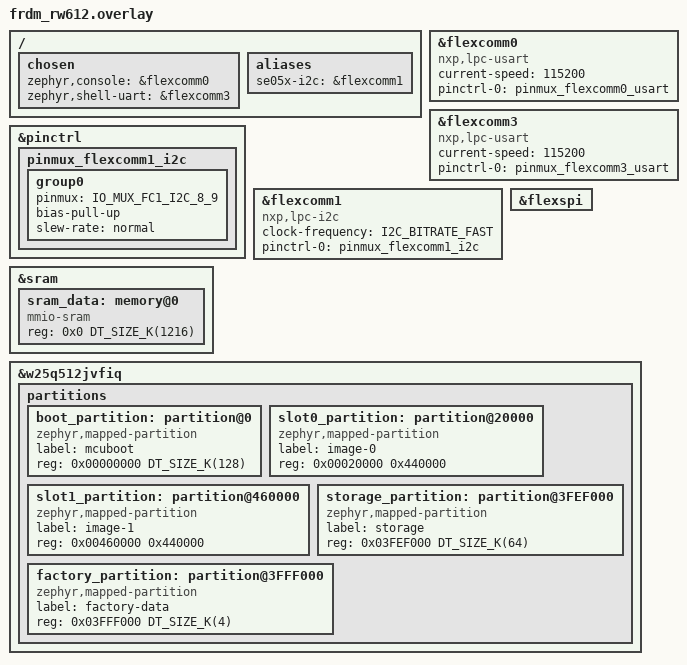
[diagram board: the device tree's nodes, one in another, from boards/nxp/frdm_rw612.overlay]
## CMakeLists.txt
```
#
#    Copyright (c) 2026 Project CHIP Authors
#
#    Licensed under the Apache License, Version 2.0 (the "License");
#    you may not use this file except in compliance with the License.
#    You may obtain a copy of the License at
#
#        http://www.apache.org/licenses/LICENSE-2.0
#
#    Unless required by applicable law or agreed to in writing, software
#    distributed under the License is distributed on an "AS IS" BASIS,
#    WITHOUT WARRANTIES OR CONDITIONS OF ANY KIND, either express or implied.
#    See the License for the specific language governing permissions and
#    limitations under the License.
#
cmake_minimum_required(VERSION 3.20)

# You may point this at a header that defines chip::app::AllDevices::AppTask as the
# final type of a CRTP layer chain rooted at AppTaskBase (see include/AppTask.h).
if(NOT DEFINED APP_TASK_IMPL_HEADER)
    set(APP_TASK_IMPL_HEADER "")
endif()

# Zephyr auto-discovers files directly under boards/. This also discovers
# board files in the registered vendor subdirectories.
include(${CMAKE_CURRENT_SOURCE_DIR}/cmake/board_files.cmake)
if(DEFINED BOARD)
    all_devices_board_name(${BOARD} ALL_DEVICES_BOARD_NAME)

    if(NOT SYSBUILD)
        all_devices_find_board_file(${CMAKE_CURRENT_SOURCE_DIR}/boards ${ALL_DEVICES_BOARD_NAME}.overlay
                                     ALL_DEVICES_NESTED_BOARD_OVERLAY EXCLUDE_FLAT)
        if(ALL_DEVICES_NESTED_BOARD_OVERLAY)
            list(APPEND DTC_OVERLAY_FILE ${ALL_DEVICES_NESTED_BOARD_OVERLAY})
            set(DTC_OVERLAY_FILE "${DTC_OVERLAY_FILE}" CACHE STRING "Application devicetree overlays" FORCE)
        endif()
    else()
        all_devices_find_board_file(${CMAKE_CURRENT_SOURCE_DIR}/boards ${ALL_DEVICES_BOARD_NAME}.overlay
                                     ALL_DEVICES_NESTED_BOARD_OVERLAY EXCLUDE_FLAT)
        list(REMOVE_ITEM DTC_OVERLAY_FILE ${ALL_DEVICES_NESTED_BOARD_OVERLAY})
        set(DTC_OVERLAY_FILE "${DTC_OVERLAY_FILE}" CACHE STRING "Application devicetree overlays" FORCE)
    endif()
    message(VERBOSE "BOARD=${BOARD} ALL_DEVICES_BOARD_NAME=${ALL_DEVICES_BOARD_NAME} ALL_DEVICES_NESTED_BOARD_OVERLAY=${ALL_DEVICES_NESTED_BOARD_OVERLAY} EXTRA_DTC_OVERLAY_FILE=${EXTRA_DTC_OVERLAY_FILE}")

    all_devices_find_board_file(${CMAKE_CURRENT_SOURCE_DIR}/boards ${ALL_DEVICES_BOARD_NAME}.conf
                                 ALL_DEVICES_NESTED_BOARD_CONF EXCLUDE_FLAT)
    if(ALL_DEVICES_NESTED_BOARD_CONF)
        list(APPEND EXTRA_CONF_FILE ${ALL_DEVICES_NESTED_BOARD_CONF})
    endif()

endif()

find_package(Zephyr HINTS $ENV{ZEPHYR_BASE})

# Matter is the Zephyr module "connectedhomeip"; it must be in the west manifest.
if(NOT DEFINED ZEPHYR_CONNECTEDHOMEIP_MODULE_DIR)
    message(FATAL_ERROR "Matter is not registered as a Zephyr module. Add it to your west manifest.")
endif()
set(CHIP_ROOT ${ZEPHYR_CONNECTEDHOMEIP_MODULE_DIR})
set(ALL_DEVICES_COMMON_DIR ${CHIP_ROOT}/examples/all-devices-app/all-devices-common)

# Device selection comes from Kconfig (CONFIG_ALL_DEVICES_DEVICE_*, see Kconfig.devices).
# -DALL_DEVICES_ENABLED_DEVICES="on-off-light;..." overrides it; an empty list means all devices.
if(NOT DEFINED ALL_DEVICES_ENABLED_DEVICES)
    set(ALL_DEVICES_ENABLED_DEVICES "")
    get_cmake_property(_all_devices_vars VARIABLES)
    foreach(_var IN LISTS _all_devices_vars)
        if(_var MATCHES "^CONFIG_ALL_DEVICES_DEVICE_(.+)$" AND ${_var})
            string(TOLOWER "${CMAKE_MATCH_1}" _key)
            string(REPLACE "_" "-" _key "${_key}")
            list(APPEND ALL_DEVICES_ENABLED_DEVICES "${_key}")
        endif()
    endforeach()
endif()
include(${ALL_DEVICES_COMMON_DIR}/device-factory/enabled_devices.cmake)

# Count enabled device keys to size AppTask's device array. 
get_cmake_property(_all_devices_vars VARIABLES)
set(ALL_DEVICES_ENABLED_DEVICE_COUNT 0)
foreach(_var IN LISTS _all_devices_vars)
    if(_var MATCHES "^ALL_DEVICES_ENABLE_" AND ${_var})
        math(EXPR ALL_DEVICES_ENABLED_DEVICE_COUNT "${ALL_DEVICES_ENABLED_DEVICE_COUNT} + 1")
    endif()
endforeach()

# Some keys register more than one creator, so include those additional creators as well.
foreach(_variant_key
        FAN
        FLOW_SENSOR
        HUMIDITY_SENSOR
        LIGHT_SENSOR
        OVEN
        POWER_SOURCE
        PRESSURE_SENSOR
        REFRIGERATOR
        ROOM_AIR_CONDITIONER
        SOIL_SENSOR
        TEMPERATURE_SENSOR)
    if(ALL_DEVICES_ENABLE_${_variant_key})
        math(EXPR ALL_DEVICES_ENABLED_DEVICE_COUNT "${ALL_DEVICES_ENABLED_DEVICE_COUNT} + 1")
    endif()
endforeach()

# closure registers one creator per entry of kVariants in ClosureVariants.cpp (8 in total).
if(ALL_DEVICES_ENABLE_CLOSURE)
    math(EXPR ALL_DEVICES_ENABLED_DEVICE_COUNT "${ALL_DEVICES_ENABLED_DEVICE_COUNT} + 7")
endif()

if(ALL_DEVICES_ENABLE_AIR_QUALITY_SENSOR)
    math(EXPR ALL_DEVICES_ENABLED_DEVICE_COUNT "${ALL_DEVICES_ENABLED_DEVICE_COUNT} + 3")
endif()

# window-covering registers one creator per entry of kVariants in WindowCoveringVariants.cpp (5 in total).
if(ALL_DEVICES_ENABLE_WINDOW_COVERING)
    math(EXPR ALL_DEVICES_ENABLED_DEVICE_COUNT "${ALL_DEVICES_ENABLED_DEVICE_COUNT} + 4")
endif()

# ot-config re-lists zephyr_interface's INTERFACE_COMPILE_DEFINITIONS, including
# $<COMPILE_LANGUAGE:CXX> generator expressions. openthread/CMakeLists.txt uses
# ot-config's defines to build a plain custom target, where COMPILE_LANGUAGE is
# invalid. Strip it so LLVM/Clang builds configure cleanly.
if(CONFIG_OPENTHREAD AND TARGET ot-config AND TARGET zephyr_interface)
    get_target_property(OT_CONFIG_DEFS ot-config INTERFACE_COMPILE_DEFINITIONS)
    if(OT_CONFIG_DEFS)
        list(FILTER OT_CONFIG_DEFS EXCLUDE REGEX "TARGET_PROPERTY:zephyr_interface,INTERFACE_COMPILE_DEFINITIONS")
    else()
        set(OT_CONFIG_DEFS "")
    endif()
    get_target_property(ZEPHYR_INTERFACE_DEFS zephyr_interface INTERFACE_COMPILE_DEFINITIONS)
    if(ZEPHYR_INTERFACE_DEFS)
        list(FILTER ZEPHYR_INTERFACE_DEFS EXCLUDE REGEX "COMPILE_LANGUAGE:CXX")
    else()
        set(ZEPHYR_INTERFACE_DEFS "")
    endif()
    set_target_properties(ot-config PROPERTIES
        INTERFACE_COMPILE_DEFINITIONS "${OT_CONFIG_DEFS};${ZEPHYR_INTERFACE_DEFS}")
endif()

project(matter-all-devices-zephyr)

include(${CHIP_ROOT}/src/app/chip_data_model.cmake)

target_compile_options(app PRIVATE -Werror -Wno-error=format)
if(CMAKE_C_COMPILER_ID STREQUAL "GNU")
    target_compile_options(app PRIVATE -Werror -Wno-error=maybe-uninitialized)
endif()

target_compile_definitions(app PRIVATE ALL_DEVICES_ENABLED_DEVICE_COUNT=${ALL_DEVICES_ENABLED_DEVICE_COUNT})

if (CONFIG_SOC_FAMILY_NXP_RW OR CONFIG_SOC_FAMILY_MCXW)
    include(${CMAKE_CURRENT_SOURCE_DIR}/nxp/app_common.cmake)
endif()    

if(NOT APP_TASK_IMPL_HEADER STREQUAL "")
    target_compile_definitions(app PRIVATE APP_TASK_IMPL_HEADER="${APP_TASK_IMPL_HEADER}")
endif()

target_include_directories(app PRIVATE
    ${CMAKE_CURRENT_SOURCE_DIR}
    src
    include
    ${ALL_DEVICES_COMMON_DIR}
    ${CMAKE_CURRENT_BINARY_DIR} # for generated app_config/enabled_devices.h
    ${ALL_DEVICES_EXTRA_INCLUDE_DIRS}
)

target_sources(app PRIVATE
    CHIPProjectConfig.h
    include/AppTaskBase.h
    include/AppTaskBase.ipp
    include/AppTask.h
    include/Buttons.h
    src/Buttons.cpp
    src/main.cpp

    # Identify
    include/delegates/ZephyrIdentifyDelegate.h
    src/delegates/ZephyrIdentifyDelegate.cpp

    # all-devices-common
    ${ALL_DEVICES_DEVICE_SOURCES}
    ${ALL_DEVICES_CLUSTER_SOURCES}
)

# Included by AppTaskBase.h; listed above only so it shows up in IDEs.
set_source_files_properties(include/AppTaskBase.ipp PROPERTIES HEADER_FILE_ONLY TRUE)

# Board-specific device implementation; AppTaskBase substitutes it into the factory.
if(ALL_DEVICES_ENABLE_ON_OFF_LIGHT)
    target_sources(app PRIVATE
        include/devices/ZephyrOnOffLight.h
        src/devices/ZephyrOnOffLight.cpp
    )
endif()

# Matches CHIP_DEVICE_CONFIG_ENABLE_THREAD, which AppTaskBase.ipp gates on.
if(CONFIG_OPENTHREAD)
    target_sources(app PRIVATE
        ${ALL_DEVICES_COMMON_DIR}/device/types/root-node/features/ThreadFeature.cpp
        )
endif()

if(CONFIG_CHIP_WIFI)
    target_sources(app PRIVATE
        ${ALL_DEVICES_COMMON_DIR}/device/types/root-node/features/WifiFeature.cpp
    )
endif()

if(CONFIG_CHIP_OTA_REQUESTOR)
    target_sources(app PRIVATE
        ${ALL_DEVICES_COMMON_DIR}/device/types/root-node/features/OtaFeature.cpp
        ${CHIP_ROOT}/src/app/clusters/ota-requestor/BDXDownloader.cpp
        ${CHIP_ROOT}/src/app/clusters/ota-requestor/DefaultOTARequestor.cpp
        ${CHIP_ROOT}/src/app/clusters/ota-requestor/DefaultOTARequestorDriver.cpp
        ${CHIP_ROOT}/src/app/clusters/ota-requestor/DefaultOTARequestorStorage.cpp
        ${CHIP_ROOT}/src/app/clusters/ota-requestor/ExtendedOTARequestorDriver.cpp
        ${CHIP_ROOT}/src/app/clusters/ota-requestor/OTATestEventTriggerHandler.cpp
        ${CHIP_ROOT}/src/app/clusters/ota-requestor/OTARequestorAttributes.cpp
        ${CHIP_ROOT}/src/app/clusters/ota-requestor/OTARequestorCluster.cpp
    )

    if(CONFIG_MCUBOOT_SIGNATURE_KEY_FILE STREQUAL "")
        set(ALL_DEVICES_OTA_BASE_NAME "zephyr")
    else()
        set(ALL_DEVICES_OTA_BASE_NAME "zephyr.signed")
    endif()

    if(CONFIG_CHIP_OTA_IMAGE_BUILD)
        chip_zephyr_ota_image(chip-ota-image
            INPUT_FILES ${PROJECT_BINARY_DIR}/zephyr/${ALL_DEVICES_OTA_BASE_NAME}.bin
            OUTPUT_FILE ${PROJECT_BINARY_DIR}/zephyr/${CONFIG_CHIP_OTA_IMAGE_FILE_NAME}
        )
    endif()
endif()
```

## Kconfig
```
#
# Copyright (c) 2026 Project CHIP Authors
#
# Licensed under the Apache License, Version 2.0 (the "License");
# you may not use this file except in compliance with the License.
# You may obtain a copy of the License at
#
# http://www.apache.org/licenses/LICENSE-2.0
#
# Unless required by applicable law or agreed to in writing, software
# distributed under the License is distributed on an "AS IS" BASIS,
# WITHOUT WARRANTIES OR CONDITIONS OF ANY KIND, either express or implied.
# See the License for the specific language governing permissions and
# limitations under the License.
#

mainmenu "Matter All-Devices Zephyr"

rsource "$(ZEPHYR_CONNECTEDHOMEIP_MODULE_DIR)/config/zephyr/chip-module/Kconfig.defaults"
rsource "Kconfig.defaults"
rsource "Kconfig.devices"

if NET_L2_OPENTHREAD
choice OPENTHREAD_DEVICE_TYPE
	default OPENTHREAD_FTD
endchoice
endif # NET_L2_OPENTHREAD

source "Kconfig.zephyr"
```

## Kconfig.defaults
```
#
# Copyright (c) 2026 Project CHIP Authors
#
# Licensed under the Apache License, Version 2.0 (the "License");
# you may not use this file except in compliance with the License.
# You may obtain a copy of the License at
#
# http://www.apache.org/licenses/LICENSE-2.0
#
# Unless required by applicable law or agreed to in writing, software
# distributed under the License is distributed on an "AS IS" BASIS,
# WITHOUT WARRANTIES OR CONDITIONS OF ANY KIND, either express or implied.
# See the License for the specific language governing permissions and
# limitations under the License.
#


if CHIP

choice STD_CPP
	default STD_CPP17
endchoice

config CHIP_ENABLE_PAIRING_AUTOSTART
	default y

# The app builds its data model at run time.
config CHIP_DATA_MODEL_CODEDRIVEN
	default y

config CHIP_ENABLE_GROUPCAST
	default y

config CHIP_PERSISTENT_SUBSCRIPTIONS
	default y

config CHIP_OTA_REQUESTOR
	default n

config IMG_MANAGER
	default y if CHIP_OTA_BACKEND_MCUBOOT

config STREAM_FLASH
	default n

config STREAM_FLASH_ERASE
	default n

config BOOTLOADER_MCUBOOT
	default y if CHIP_OTA_BACKEND_MCUBOOT

config CHIP_OTA_BACKEND_MCUBOOT
	imply STREAM_FLASH
	imply STREAM_FLASH_ERASE

config BT
	default y

config BT_PERIPHERAL
	default y

config BT_DEVICE_NAME
	default "MatterAllDev"

config BT_HOST_CRYPTO
	default y

config MBEDTLS_ENTROPY_C
	default y

config MBEDTLS_PSA_DRIVER_GET_ENTROPY
	default y

config LOG
	default y

choice LOG_MODE
	default LOG_MODE_DEFERRED
endchoice

config SYSTEM_WORKQUEUE_STACK_SIZE
	default 4096

config THREAD_LOCAL_STORAGE
	default y

config CHIP_TASK_STACK_SIZE
	default 10240

if NET_L2_OPENTHREAD

config OPENTHREAD_THREAD_STACK_SIZE
	default 6144

endif # NET_L2_OPENTHREAD

choice POSIX_AEP_CHOICE
	default POSIX_AEP_CHOICE_NONE
endchoice

config MBEDTLS
	default y

choice CHIP_CRYPTO
	default CHIP_CRYPTO_PSA
endchoice

# CHIPCryptoPALPSA.cpp uses mbedtls_md_info_from_type() for SPAKE2+.
config MBEDTLS_MD_C
	default y if CHIP_CRYPTO_SPAKE2P_MBEDTLS

# Extend the maximum number of PSA key slots to fit Matter requirements
config MBEDTLS_PSA_KEY_SLOT_COUNT
	default 64

config CHIP_FACTORY_DATA
	bool "Use provisioned factory data for credentials and commissionable data"
	default n

config CHIP_LIB_SHELL
	default y

config CHIP_WIFI
	imply NET_STATISTICS
	imply NET_IPV6_ND
	imply NET_IPV6_NBR_CACHE
	imply NET_STATISTICS_IPV6
	imply NET_STATISTICS_USER_API

config CHIP_ENABLE_WIFI_STATION
	default y if CHIP_WIFI

if CHIP_WIFI
config NET_IF_IPV6_PREFIX_COUNT
	default NET_IF_UNICAST_IPV6_ADDR_COUNT
config NET_BUF_DATA_SIZE
	default 512
endif

if SHELL

config SHELL_STACK_SIZE
    default 2616 if CHIP_WIFI

config SHELL_MINIMAL
    default y

config KERNEL_SHELL
    default n

config SHELL_WILDCARD
	default n

config CLOCK_CONTROL_NRF_SHELL
    default n

config HWINFO_SHELL
    default n

endif # SHELL

endif # CHIP
```

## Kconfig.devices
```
#
# Copyright (c) 2026 Project CHIP Authors
#
# Licensed under the Apache License, Version 2.0 (the "License");
# you may not use this file except in compliance with the License.
# You may obtain a copy of the License at
#
# http://www.apache.org/licenses/LICENSE-2.0
#
# Unless required by applicable law or agreed to in writing, software
# distributed under the License is distributed on an "AS IS" BASIS,
# WITHOUT WARRANTIES OR CONDITIONS OF ANY KIND, either express or implied.
# See the License for the specific language governing permissions and
# limitations under the License.
#

# One option per device type of the all-devices device factory. The CMake build
# maps each enabled symbol back to its registry key
# (ALL_DEVICES_DEVICE_ON_OFF_LIGHT -> "on-off-light").
#
# Keep in sync with the device list in
# all-devices-common/device-factory/enabled_devices.cmake.

menu "Matter device types"

config ALL_DEVICES_DEVICE_AGGREGATOR
	bool "Aggregator"

config ALL_DEVICES_DEVICE_AIR_PURIFIER
	bool "Air purifier"

config ALL_DEVICES_DEVICE_AIR_QUALITY_SENSOR
	bool "Air quality sensor"

config ALL_DEVICES_DEVICE_AMBIENT_CONTEXT_SENSOR
	bool "Ambient context sensor"

config ALL_DEVICES_DEVICE_BATTERY_STORAGE
	bool "Battery storage"

config ALL_DEVICES_DEVICE_BRIDGED_NODE
	bool "Bridged node"

config ALL_DEVICES_DEVICE_CHIME
	bool "Chime"

config ALL_DEVICES_DEVICE_CLOSURE
	bool "Closure"

config ALL_DEVICES_DEVICE_COLOR_TEMPERATURE_LIGHT
	bool "Color temperature light"

config ALL_DEVICES_DEVICE_COMMISSIONING_PROXY
	bool "Commissioning by proxy"

config ALL_DEVICES_DEVICE_CONTACT_SENSOR
	bool "Contact sensor"

config ALL_DEVICES_DEVICE_COOKTOP
	bool "Cooktop"

config ALL_DEVICES_DEVICE_DEVICE_ENERGY_MANAGEMENT
	bool "Device energy management"

config ALL_DEVICES_DEVICE_DIMMABLE_LIGHT
	bool "Dimmable light"

config ALL_DEVICES_DEVICE_DIMMABLE_PLUG_IN_UNIT
	bool "Dimmable plug-in unit"

config ALL_DEVICES_DEVICE_DISHWASHER
	bool "Dishwasher"

config ALL_DEVICES_DEVICE_DOORBELL
	bool "Doorbell"

config ALL_DEVICES_DEVICE_ELECTRICAL_ENERGY_TARIFF
	bool "Electrical energy tariff"

config ALL_DEVICES_DEVICE_ELECTRICAL_SENSOR
	bool "Electrical sensor"

config ALL_DEVICES_DEVICE_EXTENDED_COLOR_LIGHT
	bool "Extended color light"

config ALL_DEVICES_DEVICE_EXTRACTOR_HOOD
	bool "Extractor hood"

config ALL_DEVICES_DEVICE_FAN
	bool "Fan"

config ALL_DEVICES_DEVICE_FLOW_SENSOR
	bool "Flow sensor"

config ALL_DEVICES_DEVICE_GENERIC_SWITCH
	bool "Generic switch"

config ALL_DEVICES_DEVICE_HUMIDITY_CONDITIONER
	bool "Humidity conditioner"

config ALL_DEVICES_DEVICE_HUMIDITY_SENSOR
	bool "Humidity sensor"

config ALL_DEVICES_DEVICE_IRRIGATION_SYSTEM
	bool "Irrigation system"

config ALL_DEVICES_DEVICE_LAUNDRY_DRYER
	bool "Laundry dryer"

config ALL_DEVICES_DEVICE_LAUNDRY_WASHER
	bool "Laundry washer"

config ALL_DEVICES_DEVICE_LIGHT_SENSOR
	bool "Light sensor"

config ALL_DEVICES_DEVICE_MICROWAVE_OVEN
	bool "Microwave oven"

config ALL_DEVICES_DEVICE_MODE_SELECT
	bool "Mode select"

config ALL_DEVICES_DEVICE_MOUNTED_DIMMABLE_LOAD_CONTROL
	bool "Mounted dimmable load control"

config ALL_DEVICES_DEVICE_MOUNTED_ON_OFF_CONTROL
	bool "Mounted on/off control"

config ALL_DEVICES_DEVICE_NETWORK_INFRASTRUCTURE_MANAGER
	bool "Network infrastructure manager"

config ALL_DEVICES_DEVICE_OCCUPANCY_SENSOR
	bool "Occupancy sensor"

config ALL_DEVICES_DEVICE_ON_OFF_LIGHT
	bool "On/off light"
	default y

config ALL_DEVICES_DEVICE_ON_OFF_LIGHT_SWITCH
	bool "On/off light switch"

config ALL_DEVICES_DEVICE_ON_OFF_PLUG_IN_UNIT
	bool "On/off plug-in unit"

config ALL_DEVICES_DEVICE_OVEN
	bool "Oven"

config ALL_DEVICES_DEVICE_POWER_SOURCE
	bool "Power source"

config ALL_DEVICES_DEVICE_PRESSURE_SENSOR
	bool "Pressure sensor"

config ALL_DEVICES_DEVICE_PROXIMITY_RANGER
	bool "Proximity ranger"

config ALL_DEVICES_DEVICE_RAIN_SENSOR
	bool "Rain sensor"

config ALL_DEVICES_DEVICE_REFRIGERATOR
	bool "Refrigerator"

config ALL_DEVICES_DEVICE_ROBOTIC_VACUUM_CLEANER
	bool "Robotic vacuum cleaner"

config ALL_DEVICES_DEVICE_ROOM_AIR_CONDITIONER
	bool "Room air conditioner"

config ALL_DEVICES_DEVICE_SMOKE_CO_ALARM
	bool "Smoke/CO alarm"

config ALL_DEVICES_DEVICE_SOIL_SENSOR
	bool "Soil sensor"

config ALL_DEVICES_DEVICE_SPEAKER
	bool "Speaker"

config ALL_DEVICES_DEVICE_TEMPERATURE_SENSOR
	bool "Temperature sensor"

config ALL_DEVICES_DEVICE_THERMOSTAT
	bool "Thermostat"
config ALL_DEVICES_DEVICE_THREAD_BORDER_ROUTER
	bool "Thread border router"

config ALL_DEVICES_DEVICE_WATER_FREEZE_DETECTOR
	bool "Water freeze detector"

config ALL_DEVICES_DEVICE_WATER_HEATER
	bool "Water heater"

config ALL_DEVICES_DEVICE_WATER_LEAK_DETECTOR
	bool "Water leak detector"

config ALL_DEVICES_DEVICE_WATER_VALVE
	bool "Water valve"

config ALL_DEVICES_DEVICE_WINDOW_COVERING
	bool "WindowCovering"

endmenu
```

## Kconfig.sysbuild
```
#
#    Copyright (c) 2026 Project CHIP Authors
#
#    Licensed under the Apache License, Version 2.0 (the "License");
#    you may not use this file except in compliance with the License.
#    You may obtain a copy of the License at
#
#        http://www.apache.org/licenses/LICENSE-2.0
#
#    Unless required by applicable law or agreed to in writing, software
#    distributed under the License is distributed on an "AS IS" BASIS,
#    WITHOUT WARRANTIES OR CONDITIONS OF ANY KIND, either express or implied.
#    See the License for the specific language governing permissions and
#    limitations under the License.
#

source "${ZEPHYR_BASE}/share/sysbuild/Kconfig"

if BOOTLOADER_MCUBOOT

choice MCUBOOT_MODE
	default MCUBOOT_MODE_OVERWRITE_ONLY
endchoice

endif # BOOTLOADER_MCUBOOT
```

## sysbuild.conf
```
#
#    Copyright (c) 2026 Project CHIP Authors
#
#    Licensed under the Apache License, Version 2.0 (the "License");
#    you may not use this file except in compliance with the License.
#    You may obtain a copy of the License at
#
#        http://www.apache.org/licenses/LICENSE-2.0
#
#    Unless required by applicable law or agreed to in writing, software
#    distributed under the License is distributed on an "AS IS" BASIS,
#    WITHOUT WARRANTIES OR CONDITIONS OF ANY KIND, either express or implied.
#    See the License for the specific language governing permissions and
#    limitations under the License.
#

SB_CONFIG_BOOTLOADER_MCUBOOT=n
SB_CONFIG_MERGED_HEX_FILES=n

SB_CONFIG_MCUBOOT_MODE_OVERWRITE_ONLY=n
```

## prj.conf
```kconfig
#
#    Copyright (c) 2026 Project CHIP Authors
#
#    Licensed under the Apache License, Version 2.0 (the "License");
#    you may not use this file except in compliance with the License.
#    You may obtain a copy of the License at
#
#        http://www.apache.org/licenses/LICENSE-2.0
#
#    Unless required by applicable law or agreed to in writing, software
#    distributed under the License is distributed on an "AS IS" BASIS,
#    WITHOUT WARRANTIES OR CONDITIONS OF ANY KIND, either express or implied.
#    See the License for the specific language governing permissions and
#    limitations under the License.
#

CONFIG_CHIP=y
CONFIG_LOG_DEFAULT_LEVEL=3
CONFIG_CHIP_PROJECT_CONFIG="CHIPProjectConfig.h"
CONFIG_OPENTHREAD_SHELL=n

# Application requirements. Set here (not as Kconfig defaults) so they are not
# overridden by the shared Matter/vendor defaults sourced in Kconfig.defaults.
CONFIG_MAIN_STACK_SIZE=12288
CONFIG_MBEDTLS_HEAP_SIZE=8192

CONFIG_BUILD_OUTPUT_HEX=y
```

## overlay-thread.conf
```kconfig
#
#    Copyright (c) 2026 Project CHIP Authors
#
#    Licensed under the Apache License, Version 2.0 (the "License");
#    you may not use this file except in compliance with the License.
#    You may obtain a copy of the License at
#
#        http://www.apache.org/licenses/LICENSE-2.0
#
#    Unless required by applicable law or agreed to in writing, software
#    distributed under the License is distributed on an "AS IS" BASIS,
#    WITHOUT WARRANTIES OR CONDITIONS OF ANY KIND, either express or implied.
#    See the License for the specific language governing permissions and
#    limitations under the License.
#

# Matter over Thread instead of Wi-Fi on the ESP32-C6:
# west build ... -- -DEXTRA_CONF_FILE=overlay-thread.conf
# Values follow examples/lighting-app/esp32_zephyr/overlay-thread.conf.

CONFIG_OPENTHREAD=y
CONFIG_NET_L2_OPENTHREAD=y
CONFIG_OPENTHREAD_MANUAL_START=y
CONFIG_OPENTHREAD_SLAAC=y

# Turns the Wi-Fi stack off entirely
CONFIG_WIFI=n
CONFIG_CHIP_WIFI=n
CONFIG_NET_STATISTICS_WIFI=n

CONFIG_NET_IPV4=n
CONFIG_NET_DHCPV4=n

CONFIG_OPENTHREAD_THREAD_STACK_SIZE=6144

CONFIG_OPENTHREAD_THREAD_VERSION_1_3=y
CONFIG_OPENTHREAD_MLR=y
CONFIG_OPENTHREAD_DUA=y
CONFIG_OPENTHREAD_LINK_METRICS_INITIATOR=y
CONFIG_OPENTHREAD_LINK_METRICS_SUBJECT=y

CONFIG_NET_PKT_RX_COUNT=20
CONFIG_NET_PKT_TX_COUNT=20
CONFIG_NET_BUF_RX_COUNT=32
CONFIG_NET_BUF_TX_COUNT=32
CONFIG_NET_TX_STACK_SIZE=2048
CONFIG_NET_RX_STACK_SIZE=2048

CONFIG_NET_IPV6_ND=n
CONFIG_NET_IPV6_NBR_CACHE=n
```

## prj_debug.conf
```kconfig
#
#    Copyright (c) 2026 Project CHIP Authors
#
#    Licensed under the Apache License, Version 2.0 (the "License");
#    you may not use this file except in compliance with the License.
#    You may obtain a copy of the License at
#
#        http://www.apache.org/licenses/LICENSE-2.0
#
#    Unless required by applicable law or agreed to in writing, software
#    distributed under the License is distributed on an "AS IS" BASIS,
#    WITHOUT WARRANTIES OR CONDITIONS OF ANY KIND, either express or implied.
#    See the License for the specific language governing permissions and
#    limitations under the License.
#

# west build ... -- -DFILE_SUFFIX=debug

CONFIG_CHIP=y
CONFIG_CHIP_PROJECT_CONFIG="CHIPProjectConfig.h"

# Application requirements. Set here (not as Kconfig defaults) so they are not
# overridden by the shared Matter/vendor defaults sourced in Kconfig.defaults.
CONFIG_MAIN_STACK_SIZE=12288
CONFIG_MBEDTLS_HEAP_SIZE=8192

# Thread introspection: names threads and lists them via the "kernel threads"
# shell command.
CONFIG_THREAD_NAME=y
CONFIG_THREAD_MONITOR=y

# Zero-fills thread stacks at creation and checks a canary word on each
# context switch, so stack overflows/high-water-marks can be diagnosed.
CONFIG_INIT_STACKS=y
CONFIG_STACK_SENTINEL=y

# OpenThread CLI ("ot ...") commands on top of the Matter shell.
CONFIG_OPENTHREAD_SHELL=y

# Verbose application + Matter stack logging.
CONFIG_LOG_DEFAULT_LEVEL=4
CONFIG_CHIP_APP_LOG_LEVEL=4
CONFIG_LOG_INFO_COLOR_GREEN=y
CONFIG_LOG_DBG_COLOR_BLUE=y

# OTA Requestor (MCUboot stream flash / image manager come from Kconfig.defaults)
CONFIG_CHIP_OTA_REQUESTOR=y

# Full __ASSERT() checking (adds spinlock validation and per-assert file info).
CONFIG_ASSERT=y
CONFIG_HW_STACK_PROTECTION=y

CONFIG_SHELL=y
CONFIG_CHIP_LIB_SHELL=y

CONFIG_CONSOLE=y
CONFIG_UART_CONSOLE=y
CONFIG_SERIAL=y
CONFIG_LOG=y
CONFIG_PRINTK=y
CONFIG_PRINTK_SYNC=n
CONFIG_BOOT_BANNER=y
```

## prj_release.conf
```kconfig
#
#    Copyright (c) 2026 Project CHIP Authors
#
#    Licensed under the Apache License, Version 2.0 (the "License");
#    you may not use this file except in compliance with the License.
#    You may obtain a copy of the License at
#
#        http://www.apache.org/licenses/LICENSE-2.0
#
#    Unless required by applicable law or agreed to in writing, software
#    distributed under the License is distributed on an "AS IS" BASIS,
#    WITHOUT WARRANTIES OR CONDITIONS OF ANY KIND, either express or implied.
#    See the License for the specific language governing permissions and
#    limitations under the License.
#

# west build ... -- -DFILE_SUFFIX=release

CONFIG_CHIP=y
CONFIG_CHIP_PROJECT_CONFIG="CHIPProjectConfig.h"

# Application requirements. Set here (not as Kconfig defaults) so they are not
# overridden by the shared Matter/vendor defaults sourced in Kconfig.defaults.
CONFIG_MAIN_STACK_SIZE=12288
CONFIG_MBEDTLS_HEAP_SIZE=8192

CONFIG_USE_SEGGER_RTT=n

# No shell (Matter or OT) in a release build.
CONFIG_SHELL=n
CONFIG_CHIP_LIB_SHELL=n

# No console/log output path at all.
CONFIG_CONSOLE=n
CONFIG_UART_CONSOLE=n
CONFIG_SERIAL=n
CONFIG_LOG=n
CONFIG_PRINTK=n
CONFIG_PRINTK_SYNC=n
CONFIG_BOOT_BANNER=n

# Development aids
CONFIG_ASSERT=n

# Use Factory Data
# Requires providing a custom implementation
CONFIG_CHIP_FACTORY_DATA=y

# OTA
CONFIG_CHIP_OTA_REQUESTOR=y
CONFIG_CHIP_OTA_IMAGE_BUILD=y
CONFIG_CHIP_DEVICE_SOFTWARE_VERSION=1
CONFIG_CHIP_DEVICE_SOFTWARE_VERSION_STRING="1.0"
CONFIG_MCUBOOT_IMGTOOL_SIGN_VERSION="1.0.0+0"
```

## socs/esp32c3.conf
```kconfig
#
#    Copyright (c) 2026 Project CHIP Authors
#
#    Licensed under the Apache License, Version 2.0 (the "License");
#    you may not use this file except in compliance with the License.
#    You may obtain a copy of the License at
#
#        http://www.apache.org/licenses/LICENSE-2.0
#
#    Unless required by applicable law or agreed to in writing, software
#    distributed under the License is distributed on an "AS IS" BASIS,
#    WITHOUT WARRANTIES OR CONDITIONS OF ANY KIND, either express or implied.
#    See the License for the specific language governing permissions and
#    limitations under the License.
#

# ESP32-C3: Matter over Wi-Fi. Values follow examples/lighting-app/esp32_zephyr.

# Matter over Wi-Fi with the ESP32-native driver (no WPA supplicant)
CONFIG_WIFI=y
CONFIG_NET_IPV4=y
CONFIG_NET_DHCPV4=y
# The esp32 driver only registers with the Wi-Fi network manager in AP+STA mode
CONFIG_WIFI_NM=n

# Wi-Fi statistics used by the Matter diagnostics clusters
CONFIG_NET_STATISTICS_WIFI=y

CONFIG_NET_IF_MCAST_IPV6_ADDR_COUNT=14

# Network buffers, trimmed for the C3 SRAM
CONFIG_NET_PKT_RX_COUNT=8
CONFIG_NET_PKT_TX_COUNT=8
CONFIG_NET_BUF_RX_COUNT=16
CONFIG_NET_BUF_TX_COUNT=16
CONFIG_NET_BUF_DATA_SIZE=128

# BLE host buffers: CHIPoBLE uses one connection and short BTP windows
CONFIG_BT_RX_STACK_SIZE=4096
CONFIG_BT_BUF_EVT_RX_COUNT=10
CONFIG_BT_BUF_ACL_TX_COUNT=6
CONFIG_BT_L2CAP_TX_BUF_COUNT=6
CONFIG_BT_ATT_TX_COUNT=6
# BLE controller: one peripheral connection plus advertising is enough
CONFIG_ESP32_BT_CTLR_LE_MAX_CONN=1
CONFIG_ESP32_BT_CTLR_LE_MAX_ACT=2

# Crypto: PSA backend; key pairs are imported from storage and exported for it
CONFIG_PSA_WANT_KEY_TYPE_ECC_KEY_PAIR_IMPORT=y
CONFIG_PSA_WANT_KEY_TYPE_ECC_KEY_PAIR_EXPORT=y

# Persistent storage
CONFIG_NVS_LOOKUP_CACHE=y

# Software stack protection (no PMP stack guard on the C3) and stack high-water marks
CONFIG_STACK_CANARIES=y
CONFIG_INIT_STACKS=y

# Logging
CONFIG_LOG_MODE_IMMEDIATE=y
CONFIG_THREAD_NAME=y

# No shell in the default profile; prj_debug.conf enables it
CONFIG_SHELL=n
CONFIG_CHIP_LIB_SHELL=n

CONFIG_MAX_EVENT_QUEUE_SIZE=16
```

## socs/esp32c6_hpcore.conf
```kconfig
#
#    Copyright (c) 2026 Project CHIP Authors
#
#    Licensed under the Apache License, Version 2.0 (the "License");
#    you may not use this file except in compliance with the License.
#    You may obtain a copy of the License at
#
#        http://www.apache.org/licenses/LICENSE-2.0
#
#    Unless required by applicable law or agreed to in writing, software
#    distributed under the License is distributed on an "AS IS" BASIS,
#    WITHOUT WARRANTIES OR CONDITIONS OF ANY KIND, either express or implied.
#    See the License for the specific language governing permissions and
#    limitations under the License.
#

# ESP32-C6: Matter over Wi-Fi by default, overlay-thread.conf selects Thread.
# Values follow examples/lighting-app/esp32_zephyr.

# Matter over Wi-Fi with the ESP32-native driver (no WPA supplicant)
CONFIG_NET_L2_OPENTHREAD=n
CONFIG_WIFI=y
CONFIG_NET_IPV4=y
CONFIG_NET_DHCPV4=y
# The esp32 driver only registers with the Wi-Fi network manager in AP+STA mode
CONFIG_WIFI_NM=n

# Wi-Fi statistics used by the Matter diagnostics clusters
CONFIG_NET_STATISTICS_WIFI=y

CONFIG_NET_IF_MCAST_IPV6_ADDR_COUNT=14

# Network buffers, trimmed for the C6 SRAM
CONFIG_NET_PKT_RX_COUNT=12
CONFIG_NET_PKT_TX_COUNT=12
CONFIG_NET_BUF_RX_COUNT=24
CONFIG_NET_BUF_TX_COUNT=24
CONFIG_NET_BUF_DATA_SIZE=128

# BLE host
CONFIG_BT_RX_STACK_SIZE=4096
# BLE controller: one peripheral connection plus advertising is enough
CONFIG_ESP32_BT_CTLR_LE_MAX_CONN=1
CONFIG_ESP32_BT_CTLR_LE_MAX_ACT=2

# Crypto: PSA backend; key pairs are imported from storage and exported for it
CONFIG_PSA_WANT_KEY_TYPE_ECC_KEY_PAIR_IMPORT=y
CONFIG_PSA_WANT_KEY_TYPE_ECC_KEY_PAIR_EXPORT=y

# Persistent storage
CONFIG_NVS_LOOKUP_CACHE=y

# Stack protection (no PMP stack guard on the C6) and stack high-water marks
CONFIG_HW_STACK_PROTECTION=n
CONFIG_STACK_CANARIES=y
CONFIG_INIT_STACKS=y

# Logging
CONFIG_LOG_MODE_IMMEDIATE=y
CONFIG_THREAD_NAME=y

# No shell in the default profile; prj_debug.conf enables it
CONFIG_SHELL=n
CONFIG_CHIP_LIB_SHELL=n

CONFIG_MAX_EVENT_QUEUE_SIZE=16

# Project configuration with the ESP32 buffer sizes
CONFIG_CHIP_PROJECT_CONFIG="boards/espressif/CHIPProjectConfig.h"
```

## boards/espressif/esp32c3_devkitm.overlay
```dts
/*
 * Copyright (c) 2026 Project CHIP Authors
 *
 * Licensed under the Apache License, Version 2.0 (the "License");
 * you may not use this file except in compliance with the License.
 * You may obtain a copy of the License at
 *
 *     http://www.apache.org/licenses/LICENSE-2.0
 *
 * Unless required by applicable law or agreed to in writing, software
 * distributed under the License is distributed on an "AS IS" BASIS
 * WITHOUT WARRANTIES OR CONDITIONS OF ANY KIND, either express or implied.
 * See the License for the specific language governing permissions and
 * limitations under the License.
 */

/ {
	aliases {
		led0 = &light_led;
	};

	leds {
		compatible = "gpio-leds";

		/*
		 * External LED on a non-strapping pin. GPIO2, GPIO8 and GPIO9 are
		 * strapping pins on the ESP32-C3; the on-board LED is a WS2812 on GPIO8.
		 */
		light_led: led_0 {
			gpios = <&gpio0 3 GPIO_ACTIVE_HIGH>;
			label = "Matter light";
		};
	};
};

/* The board dts routes i2c0 SCL to GPIO3; release the pin for the LED. */
&i2c0 {
	status = "disabled";
};
```

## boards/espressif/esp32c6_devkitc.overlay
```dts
/*
 * Copyright (c) 2026 Project CHIP Authors
 *
 * Licensed under the Apache License, Version 2.0 (the "License");
 * you may not use this file except in compliance with the License.
 * You may obtain a copy of the License at
 *
 *     http://www.apache.org/licenses/LICENSE-2.0
 *
 * Unless required by applicable law or agreed to in writing, software
 * distributed under the License is distributed on an "AS IS" BASIS
 * WITHOUT WARRANTIES OR CONDITIONS OF ANY KIND, either express or implied.
 * See the License for the specific language governing permissions and
 * limitations under the License.
 */

/ {
	aliases {
		led0 = &light_led;
	};

	leds {
		compatible = "gpio-leds";

		/* External LED on a non-strapping pin; the on-board LED is a WS2812 on GPIO8. */
		light_led: led_0 {
			gpios = <&gpio0 2 GPIO_ACTIVE_HIGH>;
			label = "Matter light";
		};
	};
};

/* The board declares 8 MB, the DevKitM module has 4 MB. */
&flash0 {
	reg = <0x0 DT_SIZE_M(4)>;
};
```

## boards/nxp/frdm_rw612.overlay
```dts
/*
 *    Copyright (c) 2026 Project CHIP Authors
 *    All rights reserved.
 *
 *    Licensed under the Apache License, Version 2.0 (the "License");
 *    you may not use this file except in compliance with the License.
 *    You may obtain a copy of the License at
 *
 *        http: //www.apache.org/licenses/LICENSE-2.0
 *
 *    Unless required by applicable law or agreed to in writing, software
 *    distributed under the License is distributed on an "AS IS" BASIS
 *    WITHOUT WARRANTIES OR CONDITIONS OF ANY KIND, either express or implied.
 *    See the License for the specific language governing permissions and
 *    limitations under the License.
 */

/ {
	chosen {
		zephyr,console = &flexcomm0;
		zephyr,shell-uart = &flexcomm3;
	};
};

&flexcomm0 {
	compatible = "nxp,lpc-usart";
	status = "okay";
	current-speed = <115200>;
	pinctrl-0 = <&pinmux_flexcomm0_usart>;
	pinctrl-names = "default";
};

&flexcomm3 {
	compatible = "nxp,lpc-usart";
	status = "okay";
	current-speed = <115200>;
	pinctrl-0 = <&pinmux_flexcomm3_usart>;
	pinctrl-names = "default";
};

&pinctrl {
    pinmux_flexcomm1_i2c: pinmux_flexcomm1_i2c {
        group0 {
            pinmux = <IO_MUX_FC1_I2C_8_9>;
			bias-pull-up;
            slew-rate = "normal";
        };
    };
};

&flexcomm1 {
    status = "okay";
    compatible = "nxp,lpc-i2c";
    #address-cells = <1>;
    #size-cells = <0>;
    clock-frequency = <I2C_BITRATE_FAST>;
    pinctrl-0 = <&pinmux_flexcomm1_i2c>;
    pinctrl-names = "default";
};

/ {
	aliases {
		se05x-i2c = &flexcomm1;
	};
};

/delete-node/ &sram_data;
/delete-node/ &sram_code;
/delete-node/ &boot_partition;
/delete-node/ &slot0_partition;
/delete-node/ &slot1_partition;
/delete-node/ &storage_partition;

&sram {
	#address-cells = <1>;
	#size-cells = <1>;

	sram_data: memory@0 {
		compatible = "mmio-sram";
		reg = <0x0 DT_SIZE_K(1216)>;
	};
};

&flexspi {
	status = "okay";
};

&w25q512jvfiq {
	status = "okay";

	partitions {
		boot_partition: partition@0 {
			compatible = "zephyr,mapped-partition";
			label = "mcuboot";
			reg = <0x00000000 DT_SIZE_K(128)>;
		};

		slot0_partition: partition@20000 {
			compatible = "zephyr,mapped-partition";
			label = "image-0";
			reg = <0x00020000 0x440000>;
		};

		slot1_partition: partition@460000 {
			compatible = "zephyr,mapped-partition";
			label = "image-1";
			reg = <0x00460000 0x440000>;
		};

		storage_partition: partition@3FEF000 {
			compatible = "zephyr,mapped-partition";
			label = "storage";
			reg = <0x03FEF000 DT_SIZE_K(64)>;
		};

		factory_partition: partition@3FFF000 {
			compatible = "zephyr,mapped-partition";
			label = "factory-data";
			reg = <0x03FFF000 DT_SIZE_K(4)>;
		};

	};
};
```

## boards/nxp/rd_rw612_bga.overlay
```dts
/*
 *    Copyright (c) 2026 Project CHIP Authors
 *    All rights reserved.
 *
 *    Licensed under the Apache License, Version 2.0 (the "License");
 *    you may not use this file except in compliance with the License.
 *    You may obtain a copy of the License at
 *
 *        http: //www.apache.org/licenses/LICENSE-2.0
 *
 *    Unless required by applicable law or agreed to in writing, software
 *    distributed under the License is distributed on an "AS IS" BASIS
 *    WITHOUT WARRANTIES OR CONDITIONS OF ANY KIND, either express or implied.
 *    See the License for the specific language governing permissions and
 *    limitations under the License.
 */

/ {
	chosen {
		zephyr,console = &flexcomm0;
		zephyr,shell-uart = &flexcomm3;
	};
};

&flexcomm0 {
	compatible = "nxp,lpc-usart";
	status = "okay";
	current-speed = <115200>;
	pinctrl-0 = <&pinmux_flexcomm0_usart>;
	pinctrl-names = "default";
};

&flexcomm3 {
	compatible = "nxp,lpc-usart";
	status = "okay";
	current-speed = <115200>;
	pinctrl-0 = <&pinmux_flexcomm3_usart>;
	pinctrl-names = "default";
};

/delete-node/ &sram_data;
/delete-node/ &sram_code;
/delete-node/ &boot_partition;
/delete-node/ &slot0_partition;
/delete-node/ &slot1_partition;
/delete-node/ &storage_partition;

&sram {
	#address-cells = <1>;
	#size-cells = <1>;

	sram_data: memory@0 {
		compatible = "mmio-sram";
		reg = <0x0 DT_SIZE_K(1216)>;
	};
};

&flexspi {
	status = "okay";
};

&mx25u51245g {
	status = "okay";

	partitions {
		boot_partition: partition@0 {
			compatible = "zephyr,mapped-partition";
			label = "mcuboot";
			reg = <0x00000000 DT_SIZE_K(128)>;
		};

		slot0_partition: partition@20000 {
			compatible = "zephyr,mapped-partition";
			label = "image-0";
			reg = <0x00020000 0x440000>;
		};

		slot1_partition: partition@460000 {
			compatible = "zephyr,mapped-partition";
			label = "image-1";
			reg = <0x00460000 0x440000>;
		};

		storage_partition: partition@3FEF000 {
			compatible = "zephyr,mapped-partition";
			label = "storage";
			reg = <0x03FEF000 DT_SIZE_K(64)>;
		};

		factory_partition: partition@3FFF000 {
			compatible = "zephyr,mapped-partition";
			label = "factory-data";
			reg = <0x03FFF000 DT_SIZE_K(4)>;
		};

	};
};
```

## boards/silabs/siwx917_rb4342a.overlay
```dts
/*
 * Copyright (c) 2026 Project CHIP Authors
 *
 * Licensed under the Apache License, Version 2.0 (the "License");
 * you may not use this file except in compliance with the License.
 * You may obtain a copy of the License at
 *
 *     http://www.apache.org/licenses/LICENSE-2.0
 *
 * Unless required by applicable law or agreed to in writing, software
 * distributed under the License is distributed on an "AS IS" BASIS
 * WITHOUT WARRANTIES OR CONDITIONS OF ANY KIND, either express or implied.
 * See the License for the specific language governing permissions and
 * limitations under the License.
 */

&flash0 {
        partitions {
                factory_partition: partition@3e0000 {
                        reg = <0x003e0000 DT_SIZE_K(4)>;
                };

                settings_partition: partition@3e1000 {
                        reg = <0x003e1000 DT_SIZE_K(32)>;
                };
        };
};

&code_partition {
       reg = <0x00202000 DT_SIZE_K(1912)>;
};


&storage_partition {
       reg = <0x003e9000 DT_SIZE_K(92)>;
};
```

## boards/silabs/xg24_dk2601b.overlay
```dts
/*
 *	Copyright (c) 2026 Project CHIP Authors
 *	All rights reserved.
 *
 *	Licensed under the Apache License, Version 2.0 (the "License");
 *	you may not use this file except in compliance with the License.
 *	You may obtain a copy of the License at
 *
 *	    http://www.apache.org/licenses/LICENSE-2.0
 *
 *	Unless required by applicable law or agreed to in writing, software
 *	distributed under the License is distributed on an "AS IS" BASIS
 *	WITHOUT WARRANTIES OR CONDITIONS OF ANY KIND, either express or implied.
 *	See the License for the specific language governing permissions and
 *	limitations under the License.
 */

/*
 * Internal flash (1536 KiB): boot (48) + slot0 (1024) + unused (416) + storage (48).
 * External flash (1024 KiB): slot1 (1024)
 * slot1 must match for MCUboot in overwrite-only mode
 */
/delete-node/ &slot0_partition;
/delete-node/ &slot1_partition;
/delete-node/ &storage_partition;

&flash0 {
	partitions {
		slot0_partition: partition@c000 {
			compatible = "zephyr,mapped-partition";
			reg = <0x0000c000 DT_SIZE_K(1024)>;
			label = "image-0";
		};

		unused_partition: partition@10c000 {
			compatible = "zephyr,mapped-partition";
			reg = <0x0010c000 DT_SIZE_K(416)>;
			label = "unused";
		};

		storage_partition: partition@174000 {
			compatible = "zephyr,mapped-partition";
			reg = <0x00174000 DT_SIZE_K(48)>;
			label = "storage";
		};
	};
};

&mx25r32 {
	partitions {
		compatible = "fixed-partitions";
		#address-cells = <1>;
		#size-cells = <1>;

		slot1_partition: partition@0 {
			reg = <0x00000000 DT_SIZE_K(1024)>;
			label = "image-1";
		};
	};
};

&dma0 {
	status = "okay";
};

&usart0 {
	dmas = <&dma0 DMA_REQSEL_USART0TXBL>,
		   <&dma0 DMA_REQSEL_USART0RXDATAV>;
	dma-names = "tx", "rx";
};
```

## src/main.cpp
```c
/*
 *
 *    Copyright (c) 2026 Project CHIP Authors
 *    All rights reserved.
 *
 *    Licensed under the Apache License, Version 2.0 (the "License");
 *    you may not use this file except in compliance with the License.
 *    You may obtain a copy of the License at
 *
 *        http://www.apache.org/licenses/LICENSE-2.0
 *
 *    Unless required by applicable law or agreed to in writing, software
 *    distributed under the License is distributed on an "AS IS" BASIS,
 *    WITHOUT WARRANTIES OR CONDITIONS OF ANY KIND, either express or implied.
 *    See the License for the specific language governing permissions and
 *    limitations under the License.
 */

#include "AppTask.h"

#include <lib/core/CHIPError.h>
#include <zephyr/kernel.h>

#include <cstdlib>

int main()
{
    const CHIP_ERROR err = chip::app::AllDevices::GetAppTask().Run();
    if (err != CHIP_NO_ERROR)
    {
        printk("AppTask::Run() failed: %" CHIP_ERROR_FORMAT "\n", err.Format());
        return EXIT_FAILURE;
    }

    return EXIT_SUCCESS;
}
```

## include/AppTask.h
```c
/*
 *
 *    Copyright (c) 2026 Project CHIP Authors
 *    All rights reserved.
 *
 *    Licensed under the Apache License, Version 2.0 (the "License");
 *    you may not use this file except in compliance with the License.
 *    You may obtain a copy of the License at
 *
 *        http://www.apache.org/licenses/LICENSE-2.0
 *
 *    Unless required by applicable law or agreed to in writing, software
 *    distributed under the License is distributed on an "AS IS" BASIS,
 *    WITHOUT WARRANTIES OR CONDITIONS OF ANY KIND, either express or implied.
 *    See the License for the specific language governing permissions and
 *    limitations under the License.
 */

#pragma once

#include "AppTaskBase.h"

#ifdef APP_TASK_IMPL_HEADER
#include APP_TASK_IMPL_HEADER
#else

namespace chip::app::AllDevices {

class AppTask final : public AppTaskBase<AppTask>
{
};

} // namespace chip::app::AllDevices

#endif // APP_TASK_IMPL_HEADER

namespace chip::app::AllDevices {

inline AppTask gAppTask;

inline AppTask & GetAppTask()
{
    return gAppTask;
}

} // namespace chip::app::AllDevices
```

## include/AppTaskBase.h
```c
/*
 *
 *    Copyright (c) 2026 Project CHIP Authors
 *    All rights reserved.
 *
 *    Licensed under the Apache License, Version 2.0 (the "License");
 *    you may not use this file except in compliance with the License.
 *    You may obtain a copy of the License at
 *
 *        http://www.apache.org/licenses/LICENSE-2.0
 *
 *    Unless required by applicable law or agreed to in writing, software
 *    distributed under the License is distributed on an "AS IS" BASIS,
 *    WITHOUT WARRANTIES OR CONDITIONS OF ANY KIND, either express or implied.
 *    See the License for the specific language governing permissions and
 *    limitations under the License.
 */

#pragma once

#include <app/persistence/DefaultAttributePersistenceProvider.h>
#include <app/server/Server.h>
#include <binding-handler/BindingHandler.h>
#include <credentials/GroupDataProviderImpl.h>
#include <data-model-providers/codedriven/CodeDrivenDataModelProvider.h>
#include <device/api/Interface.h>
#include <device/types/root-node/RootNode.h>
#include <lib/core/CHIPError.h>
#include <platform/DefaultTimerDelegate.h>
#include <providers/AllDevicesExampleDeviceInfoProviderImpl.h>
#if CHIP_DEVICE_CONFIG_ENABLE_THREAD
#include <platform/OpenThread/GenericNetworkCommissioningThreadDriver.h>
#endif // CHIP_DEVICE_CONFIG_ENABLE_THREAD

#include "delegates/ZephyrIdentifyDelegate.h"

#if CHIP_DEVICE_CONFIG_ENABLE_WIFI
#include <platform/Zephyr/wifi/ZephyrWifiDriver.h>
#endif // CHIP_DEVICE_CONFIG_ENABLE_WIFI

#if CHIP_DEVICE_CONFIG_ENABLE_OTA_REQUESTOR
#include <app/clusters/ota-requestor/BDXDownloader.h>
#include <app/clusters/ota-requestor/DefaultOTARequestor.h>
#include <app/clusters/ota-requestor/DefaultOTARequestorDriver.h>
#include <app/clusters/ota-requestor/DefaultOTARequestorStorage.h>
#include <app/clusters/ota-requestor/OTARequestorAttributes.h>
#include <app/clusters/ota-requestor/OTARequestorCluster.h>
#endif // CHIP_DEVICE_CONFIG_ENABLE_OTA_REQUESTOR

#include <memory>

namespace chip::app::AllDevices {

/**
 * Generic Zephyr Matter application task.
 *
 * This is a CRTP base. `Derived` is the final application type. `Run()` sets the
 * order of the initialization steps and calls each step through `Self()`. To
 * replace a step, declare a step with the same name in a derived class.
 *
 * Make your custom layer a template. Then you can stack the layers:
 *
 *     template <class D> class CustomAppTask : public AppTaskBase<D> { ... };
 *     class AppTask final : public CustomAppTask<AppTask> {};
 *
 * To also run the generic behaviour, call `AppTaskBase<D>::Step()` from your step.
 */
template <class Derived>
class AppTaskBase
{
public:
    /// Runs every initialization step in order, then starts the CHIP event
    /// loop. Returns on the first failure.
    CHIP_ERROR Run();

    CHIP_ERROR InitPlatform();

    // SetDeviceAttestationCredentialsProvider and SetDeviceInstanceInfoProvider
    CHIP_ERROR InitCredentials();

    // Dispatches to InitThreadNetworking() / InitWifiNetworking().
    CHIP_ERROR InitNetwork();

    CHIP_ERROR InitThreadNetworking();

    // Binds the Zephyr Wi-Fi station driver to the optional Matter shell. The
    // driver itself is consumed by WifiFeature when it creates the root
    // Network Commissioning and Wi-Fi Network Diagnostics clusters.
    CHIP_ERROR InitWifiNetworking();

    /// Sets up persistence and registers the group data and device info providers.
    CHIP_ERROR InitPersistence();

    TestEventTriggerDelegate & GetTestEventTriggerDelegate();

    /// Identify delegate handed to every device created by the DeviceFactory.
    Clusters::IdentifyDelegate & GetIdentifyDelegate();

    CHIP_ERROR InitRootNode();

    /// Substitutes board-specific implementations
    CHIP_ERROR RegisterDeviceCreators();

    /// Instantiates every type in DeviceFactory::SupportedDeviceTypes().
    CHIP_ERROR RegisterAppDevices();

    CHIP_ERROR InitServer();

    // Factory reset button
    CHIP_ERROR InitBoardControls();

    CHIP_ERROR PostServerInit();

    CHIP_ERROR InitOTARequestor();

protected:
    static constexpr EndpointId kRootEndpointId        = 0;
    static constexpr EndpointId kFirstDeviceEndpointId = 1;

    Derived & Self() { return static_cast<Derived &>(*this); }

    chip::CommonCaseDeviceServerInitParams mInitParams;
    Credentials::GroupDataProviderImpl mGroupDataProvider;
    SimpleTestEventTriggerDelegate mDefaultTestEventTriggerDelegate;
    ZephyrIdentifyDelegate mDefaultIdentifyDelegate;
    DeviceLayer::AllDevicesExampleDeviceInfoProviderImpl mDeviceInfoProvider;
    DefaultTimerDelegate mTimerDelegate;
    BindingHandler mBindingHandler;
    DefaultAttributePersistenceProvider mAttributePersistenceProvider;

#if CHIP_DEVICE_CONFIG_ENABLE_THREAD
    DeviceLayer::NetworkCommissioning::GenericThreadDriver mThreadDriver;
#endif // CHIP_DEVICE_CONFIG_ENABLE_THREAD

#if CHIP_DEVICE_CONFIG_ENABLE_WIFI
    // Must be the singleton: WiFiManager completion callbacks call ZephyrWifiDriver::Instance().
    DeviceLayer::NetworkCommissioning::ZephyrWifiDriver & mWifiDriver =
        DeviceLayer::NetworkCommissioning::ZephyrWifiDriver::Instance();
#endif // CHIP_DEVICE_CONFIG_ENABLE_WIFI

#if CHIP_DEVICE_CONFIG_ENABLE_OTA_REQUESTOR
    chip::DefaultOTARequestor mOTARequestorCore;
    chip::DefaultOTARequestorStorage mOTARequestorStorage;
    DeviceLayer::DefaultOTARequestorDriver mOTARequestorDriver;
    chip::BDXDownloader mOTADownloader;
    chip::OTARequestorAttributes mOTARequestorAttributes;
    Clusters::OTARequestorCluster * mOTARequestorCluster = nullptr;
#endif // CHIP_DEVICE_CONFIG_ENABLE_OTA_REQUESTOR

    std::unique_ptr<RootNode> mRootNode;
    std::unique_ptr<DeviceInterface> mDevices[ALL_DEVICES_ENABLED_DEVICE_COUNT];
    size_t mDeviceCount = 0;
    std::unique_ptr<CodeDrivenDataModelProvider> mDataModelProvider;
};

} // namespace chip::app::AllDevices

#include "AppTaskBase.ipp"
```

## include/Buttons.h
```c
/*
 *
 *    Copyright (c) 2026 Project CHIP Authors
 *    All rights reserved.
 *
 *    Licensed under the Apache License, Version 2.0 (the "License");
 *    you may not use this file except in compliance with the License.
 *    You may obtain a copy of the License at
 *
 *        http://www.apache.org/licenses/LICENSE-2.0
 *
 *    Unless required by applicable law or agreed to in writing, software
 *    distributed under the License is distributed on an "AS IS" BASIS,
 *    WITHOUT WARRANTIES OR CONDITIONS OF ANY KIND, either express or implied.
 *    See the License for the specific language governing permissions and
 *    limitations under the License.
 */

#pragma once

#include <lib/core/CHIPError.h>
#include <zephyr/devicetree.h>

#if DT_NODE_EXISTS(DT_ALIAS(sw0))
#define ALL_DEVICES_FACTORY_RESET_SW_NODE DT_ALIAS(sw0)
#endif

#if defined(ALL_DEVICES_FACTORY_RESET_SW_NODE)
#define ALL_DEVICES_HAS_FACTORY_RESET_SW 1
#else
#define ALL_DEVICES_HAS_FACTORY_RESET_SW 0
#endif

namespace chip::app::AllDevices::Button {

/// Configures the factory-reset button when it exists.
CHIP_ERROR Init();

} // namespace chip::app::AllDevices::Button
```

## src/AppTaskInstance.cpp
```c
/*
 *
 *    Copyright (c) 2026 Project CHIP Authors
 *    All rights reserved.
 *
 *    Licensed under the Apache License, Version 2.0 (the "License");
 *    you may not use this file except in compliance with the License.
 *    You may obtain a copy of the License at
 *
 *        http://www.apache.org/licenses/LICENSE-2.0
 *
 *    Unless required by applicable law or agreed to in writing, software
 *    distributed under the License is distributed on an "AS IS" BASIS,
 *    WITHOUT WARRANTIES OR CONDITIONS OF ANY KIND, either express or implied.
 *    See the License for the specific language governing permissions and
 *    limitations under the License.
 */

// APP_TASK_INSTANCE_SOURCE could be set to a subclass, but by default it is this file.
#include "AppTask.h"

namespace chip::app::AllDevices {
namespace {

AppTask sAppTask;

} // namespace

AppTask & GetAppTask()
{
    return sAppTask;
}

} // namespace chip::app::AllDevices
```
